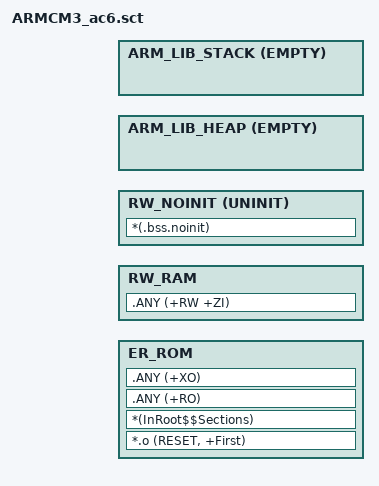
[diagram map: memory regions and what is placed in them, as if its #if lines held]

/*----------------------------------------------------------------------------
  User Stack & Heap boundary definition
 *----------------------------------------------------------------------------*/
#define __STACK_TOP    (__RAM_BASE + __RAM_SIZE)    /* starts at end of RAM */
#define __HEAP_BASE    (AlignExpr(+0, 8))           /* starts after RW_RAM section, 8 byte aligned */


/*----------------------------------------------------------------------------
  Scatter File Definitions definition
 *----------------------------------------------------------------------------*/
#define __RO_BASE       __ROM_BASE
#define __RO_SIZE       __ROM_SIZE

#define __RW_BASE       __RAM_BASE
#define __RW_SIZE      (__RAM_SIZE - __STACK_SIZE - __HEAP_SIZE - __RAM_NOINIT_SIZE)

LR_ROM __RO_BASE __RO_SIZE  {                       ; load region size_region
  ER_ROM __RO_BASE __RO_SIZE  {                     ; load address = execution address
   *.o (RESET, +First)
   *(InRoot$$Sections)
   .ANY (+RO)
   .ANY (+XO)
  }

  RW_RAM __RW_BASE __RW_SIZE  {                     ; RW data
   .ANY (+RW +ZI)
  }

#if __RAM_NOINIT_SIZE > 0
  RW_NOINIT +0 UNINIT __RAM_NOINIT_SIZE {
    *(.bss.noinit)
  }
#endif

#if __HEAP_SIZE > 0
  ARM_LIB_HEAP  __HEAP_BASE EMPTY  __HEAP_SIZE  {   ; Reserve empty region for heap
  }
#endif

  ARM_LIB_STACK __STACK_TOP EMPTY -__STACK_SIZE {   ; Reserve empty region for stack
  }
}
